AUTOSAR XML (schema 4-2-2)
package /EB/SoftwareComponents
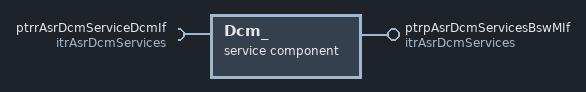
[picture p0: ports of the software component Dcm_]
  service sw component type Dcm_: category=ASR_Interfaces
    provide port ptrpAsrDcmServicesBswMIf: provided-interface=itrAsrDcmServices
    require port ptrrAsrDcmServiceDcmIf: required-interface=itrAsrDcmServices
    behavior Dcm_IB: handle-termination-and-restart=NO-SUPPORT
      4 x external trigger occurred event:
        Dcm_WriteMemory: start-on-event=Dcm_Dsp_MemoryServices_WriteMemory_ConfirmForcedRCRRP, trigger=ptrrAsrDcmServiceDcmIf.Dcm_WriteMemory
        trDcm_GetProgConditions: start-on-event=Dcm_WarmStartActions, trigger=ptrrAsrDcmServiceDcmIf.Dcm_GetProgConditions
        trDcm_ReadMemory: start-on-event=Dcm_Dsp_MemoryServices_ReadMemory_Execute, trigger=ptrrAsrDcmServiceDcmIf.Dcm_ReadMemory
        trDcm_SetProgConditions: start-on-event=Dcm_MainFunction, trigger=ptrrAsrDcmServiceDcmIf.Dcm_SetProgConditions
      5 x runnable:
        Dcm_Dsp_MemoryServices_ReadMemory_Execute
        Dcm_Dsp_MemoryServices_WriteMemory_ConfirmForcedRCRRP
        Dcm_Init
        Dcm_MainFunction
        Dcm_WarmStartActions
package /EB/TriggerInterfaces
  trigger interface itrAsrDcmServices
    6 x trigger, all with trigger-period={cse-code=1000, cse-code-factor=0}:
      Dcm_GetProgConditions
      Dcm_Init
      Dcm_ReadMemory
      Dcm_SetProgConditions
      Dcm_WriteMemory
      Rte_DcmConfirmation
